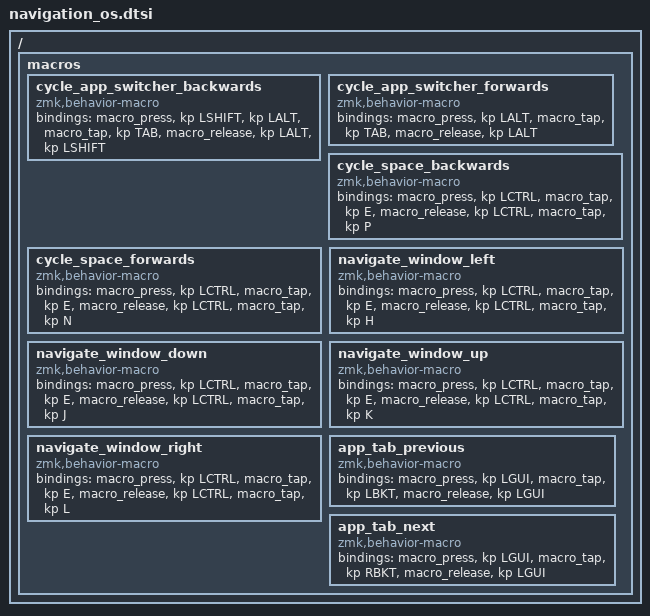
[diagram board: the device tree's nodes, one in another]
/ {
    macros {
        cycle_app_switcher_backwards: cycle_app_switcher_backwards {
            compatible = "zmk,behavior-macro";
            #binding-cells = <0>;
            bindings = <&macro_press &kp LSHIFT &kp LALT>
                     , <&macro_tap &kp TAB>
                     , <&macro_release &kp LALT &kp LSHIFT>;
        };
        cycle_app_switcher_forwards: cycle_app_switcher_forwards {
            compatible = "zmk,behavior-macro";
            #binding-cells = <0>;
            bindings = <&macro_press &kp LALT>
                     , <&macro_tap &kp TAB>
                     , <&macro_release &kp LALT>;
        };

        cycle_space_backwards: cycle_space_backwards {
            compatible = "zmk,behavior-macro";
            #binding-cells = <0>;
            bindings = <&macro_press &kp LCTRL>
                     , <&macro_tap &kp E>
                     , <&macro_release &kp LCTRL>
                     , <&macro_tap &kp P>;
        };
        cycle_space_forwards: cycle_space_forwards {
            compatible = "zmk,behavior-macro";
            #binding-cells = <0>;
            bindings = <&macro_press &kp LCTRL>
                     , <&macro_tap &kp E>
                     , <&macro_release &kp LCTRL>
                     , <&macro_tap &kp N>;
        };

        navigate_window_left: navigate_window_left {
            compatible = "zmk,behavior-macro";
            #binding-cells = <0>;
            bindings = <&macro_press &kp LCTRL>
                     , <&macro_tap &kp E>
                     , <&macro_release &kp LCTRL>
                     , <&macro_tap &kp H>;
        };

        navigate_window_down: navigate_window_down {
            compatible = "zmk,behavior-macro";
            #binding-cells = <0>;
            bindings = <&macro_press &kp LCTRL>
                     , <&macro_tap &kp E>
                     , <&macro_release &kp LCTRL>
                     , <&macro_tap &kp J>;
        };

        navigate_window_up: navigate_window_up {
            compatible = "zmk,behavior-macro";
            #binding-cells = <0>;
            bindings = <&macro_press &kp LCTRL>
                     , <&macro_tap &kp E>
                     , <&macro_release &kp LCTRL>
                     , <&macro_tap &kp K>;
        };
        navigate_window_right: navigate_window_right {
            compatible = "zmk,behavior-macro";
            #binding-cells = <0>;
            bindings = <&macro_press &kp LCTRL>
                     , <&macro_tap &kp E>
                     , <&macro_release &kp LCTRL>
                     , <&macro_tap &kp L>;
        };

        app_tab_previous: app_tab_previous {
            compatible = "zmk,behavior-macro";
            #binding-cells = <0>;
            bindings = <&macro_press &kp LGUI>
                     , <&macro_tap &kp LBKT>
                     , <&macro_release &kp LGUI>;
        };

        app_tab_next: app_tab_next {
            compatible = "zmk,behavior-macro";
            #binding-cells = <0>;
            bindings = <&macro_press &kp LGUI>
                     , <&macro_tap &kp RBKT>
                     , <&macro_release &kp LGUI>;
        };
    };
};
